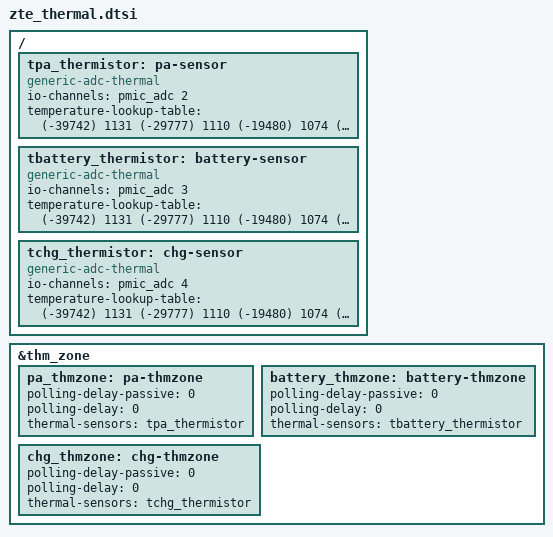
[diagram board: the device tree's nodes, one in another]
/ {
    tpa_thermistor:pa-sensor {
        compatible = "generic-adc-thermal";
        #thermal-sensor-cells = <0>;
        io-channels = <&pmic_adc 2>;
        io-channel-names = "sensor-channel";
        temperature-lookup-table = < (-39742) 1131
								(-29777) 1110
								(-19480) 1074
								(-4679) 983
								10110 838
								24805 654
								44922 413
								54903 316
								64895 238
								74884 178
								84883 133
								94883 100
								104880 75
								114889 57
								124872 43 >;
    };

    tbattery_thermistor:battery-sensor {
        compatible = "generic-adc-thermal";
        #thermal-sensor-cells = <0>;
        io-channels = <&pmic_adc 3>;
        io-channel-names = "sensor-channel";
        temperature-lookup-table = < (-39742) 1131
								(-29777) 1110
								(-19480) 1074
								(-4679) 983
								10110 838
								24805 654
								44922 413
								54903 316
								64895 238
								74884 178
								84883 133
								94883 100
								104880 75
								114889 57
								124872 43 >;
    };

    tchg_thermistor:chg-sensor {
        compatible = "generic-adc-thermal";
        #thermal-sensor-cells = <0>;
        io-channels = <&pmic_adc 4>;
        io-channel-names = "sensor-channel";
        temperature-lookup-table = < (-39742) 1131
								(-29777) 1110
								(-19480) 1074
								(-4679) 983
								10110 838
								24805 654
								44922 413
								54903 316
								64895 238
								74884 178
								84883 133
								94883 100
								104880 75
								114889 57
								124872 43 >;
    };
};

&thm_zone {
	pa_thmzone: pa-thmzone {
	polling-delay-passive = <0>;
	polling-delay = <0>;
	thermal-sensors = <&tpa_thermistor>;
	};
};

&thm_zone {
	battery_thmzone: battery-thmzone {
	polling-delay-passive = <0>;
	polling-delay = <0>;
	thermal-sensors = <&tbattery_thermistor>;
	};
};

&thm_zone {
	chg_thmzone: chg-thmzone {
	polling-delay-passive = <0>;
	polling-delay = <0>;
	thermal-sensors = <&tchg_thermistor>;
	};
};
